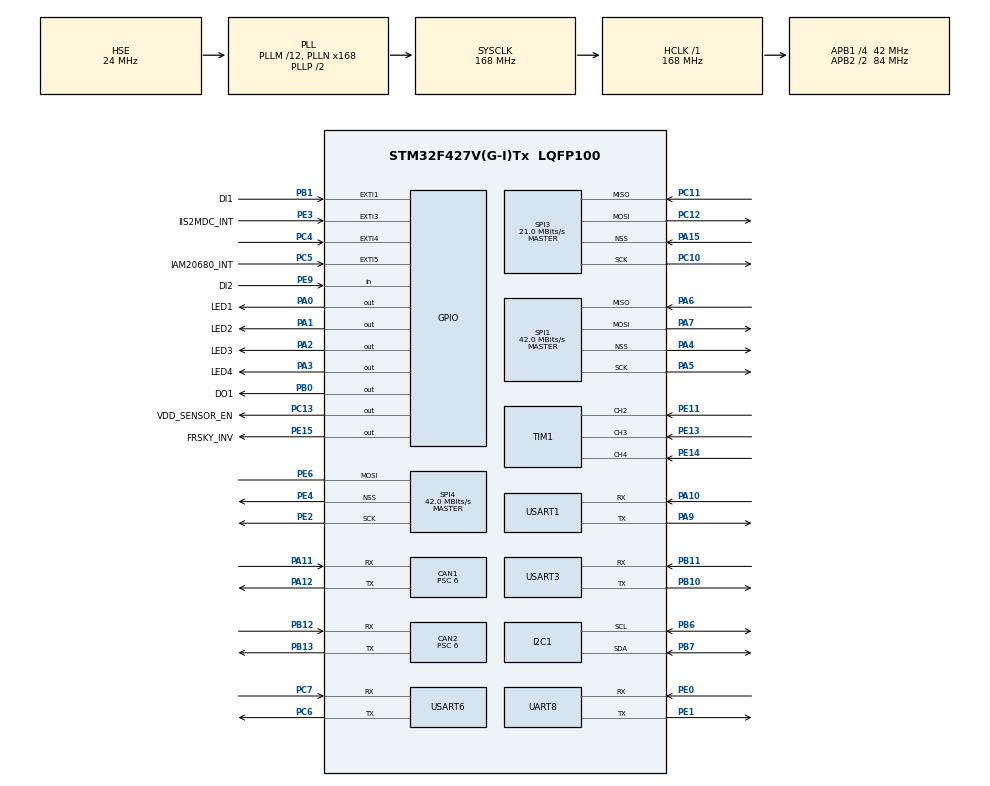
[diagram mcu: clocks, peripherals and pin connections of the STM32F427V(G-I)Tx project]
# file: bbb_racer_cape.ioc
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CAN1.BS1=CAN_BS1_11TQ
CAN1.BS2=CAN_BS2_2TQ
CAN1.CalculateBaudRate=500000
CAN1.CalculateTimeBit=1999.99
CAN1.CalculateTimeQuantum=142.85714285714286
CAN1.Prescaler=6
CAN2.BS1=CAN_BS1_11TQ
CAN2.BS2=CAN_BS2_2TQ
CAN2.CalculateBaudRate=500000
CAN2.CalculateTimeBit=1999.99
CAN2.CalculateTimeQuantum=142.85714285714286
CAN2.Prescaler=6
FREERTOS.Tasks01=defaultTask,24,128,StartDefaultTask,Default,NULL,Dynamic,NULL,NULL
FREERTOS.configENABLE_FPU=1
Mcu.Family=STM32F4
Mcu.Name=STM32F427V(G-I)Tx
Mcu.Package=LQFP100
NVIC.CAN1_RX0_IRQn=true\:5\:0\:false\:false\:true\:true\:true\:true
NVIC.CAN2_RX1_IRQn=true\:5\:0\:false\:false\:true\:true\:true\:true
NVIC.EXTI1_IRQn=true\:5\:0\:false\:false\:true\:true\:true\:true
NVIC.EXTI9_5_IRQn=true\:5\:0\:false\:false\:true\:true\:true\:true
NVIC.PriorityGroup=NVIC_PRIORITYGROUP_4
NVIC.TIM1_TRG_COM_TIM11_IRQn=true\:0\:0\:false\:false\:true\:false\:false\:true
NVIC.TimeBase=TIM1_TRG_COM_TIM11_IRQn
NVIC.TimeBaseIP=TIM11
NVIC.UART8_IRQn=true\:5\:0\:false\:false\:true\:true\:true\:true
NVIC.USART3_IRQn=true\:5\:0\:false\:false\:true\:true\:true\:true
NVIC.USART6_IRQn=true\:5\:0\:false\:false\:true\:true\:true\:true
PA0/WKUP.GPIO_Label=LED1
PA0/WKUP.Signal=GPIO_Output
PA1.GPIO_Label=LED2
PA1.Signal=GPIO_Output
PA10.Mode=Asynchronous
PA10.Signal=USART1_RX
PA11.Mode=CAN_Activate
PA11.Signal=CAN1_RX
PA12.Mode=CAN_Activate
PA12.Signal=CAN1_TX
PA13.Mode=Trace_Asynchronous_SW
PA13.Signal=SYS_JTMS-SWDIO
PA14.Mode=Trace_Asynchronous_SW
PA14.Signal=SYS_JTCK-SWCLK
PA15.Mode=NSS_Signal_Hard_Input
PA15.Signal=SPI3_NSS
PA2.GPIO_Label=LED3
PA2.Signal=GPIO_Output
PA3.GPIO_Label=LED4
PA3.Signal=GPIO_Output
PA4.Mode=NSS_Signal_Hard_Output
PA4.Signal=SPI1_NSS
PA5.Mode=Full_Duplex_Master
PA5.Signal=SPI1_SCK
PA6.Mode=Full_Duplex_Master
PA6.Signal=SPI1_MISO
PA7.Mode=Full_Duplex_Master
PA7.Signal=SPI1_MOSI
PA9.Mode=Asynchronous
PA9.Signal=USART1_TX
PB0.GPIO_Label=DO1
PB0.Signal=GPIO_Output
PB1.GPIO_Label=DI1
PB1.GPIO_PuPd=GPIO_PULLDOWN
PB1.Signal=GPXTI1
PB10.Mode=Asynchronous
PB10.Signal=USART3_TX
PB11.Mode=Asynchronous
PB11.Signal=USART3_RX
PB12.Mode=CAN_Activate
PB12.Signal=CAN2_RX
PB13.Mode=CAN_Activate
PB13.Signal=CAN2_TX
PB3.Mode=Trace_Asynchronous_SW
PB3.Signal=SYS_JTDO-SWO
PB6.Mode=I2C
PB6.Signal=I2C1_SCL
PB7.Mode=I2C
PB7.Signal=I2C1_SDA
PC10.Mode=Full_Duplex_Master
PC10.Signal=SPI3_SCK
PC11.Mode=Full_Duplex_Master
PC11.Signal=SPI3_MISO
PC12.Mode=Full_Duplex_Master
PC12.Signal=SPI3_MOSI
PC13.GPIO_Label=VDD_SENSOR_EN
PC13.Signal=GPIO_Output
PC4.Signal=GPXTI4
PC5.GPIO_Label=IAM20680_INT
PC5.Signal=GPXTI5
PC6.Mode=Asynchronous
PC6.Signal=USART6_TX
PC7.Mode=Asynchronous
PC7.Signal=USART6_RX
PE0.Mode=Asynchronous
PE0.Signal=UART8_RX
PE1.Mode=Asynchronous
PE1.Signal=UART8_TX
PE11.Signal=S_TIM1_CH2
PE13.Signal=S_TIM1_CH3
PE14.Signal=S_TIM1_CH4
PE15.GPIO_Label=FRSKY_INV
PE15.Signal=GPIO_Output
PE2.Mode=Simplex_Bidirectional_Master
PE2.Signal=SPI4_SCK
PE3.GPIO_Label=IIS2MDC_INT
PE3.Signal=GPXTI3
PE4.Mode=NSS_Signal_Hard_Output
PE4.Signal=SPI4_NSS
PE6.Mode=Simplex_Bidirectional_Master
PE6.Signal=SPI4_MOSI
PE9.GPIO_Label=DI2
PE9.Signal=GPIO_Input
PH0/OSC_IN.Mode=HSE-External-Oscillator
PH0/OSC_IN.Signal=RCC_OSC_IN
PH1/OSC_OUT.Mode=HSE-External-Oscillator
PH1/OSC_OUT.Signal=RCC_OSC_OUT
ProjectManager.HeapSize=0x200
ProjectManager.StackSize=0x400
ProjectManager.TargetToolchain=Makefile
RCC.48MHZClocksFreq_Value=84000000
RCC.AHBFreq_Value=168000000
RCC.APB1CLKDivider=RCC_HCLK_DIV4
RCC.APB1Freq_Value=42000000
RCC.APB1TimFreq_Value=84000000
RCC.APB2CLKDivider=RCC_HCLK_DIV2
RCC.APB2Freq_Value=84000000
RCC.APB2TimFreq_Value=168000000
RCC.CortexFreq_Value=168000000
RCC.HCLKFreq_Value=168000000
RCC.HSE_VALUE=24000000
RCC.HSI_VALUE=16000000
RCC.LSE_VALUE=32768
RCC.PLLM=12
RCC.PLLN=168
RCC.PLLSourceVirtual=RCC_PLLSOURCE_HSE
RCC.SYSCLKFreq_VALUE=168000000
RCC.SYSCLKSource=RCC_SYSCLKSOURCE_PLLCLK
RCC.VCOOutputFreq_Value=336000000
SH.S_TIM1_CH2.0=TIM1_CH2,Input_Capture2_from_TI2
SH.S_TIM1_CH3.0=TIM1_CH3,Input_Capture3_from_TI3
SH.S_TIM1_CH4.0=TIM1_CH4,Input_Capture4_from_TI4
SPI1.BaudRatePrescaler=SPI_BAUDRATEPRESCALER_2
SPI1.CalculateBaudRate=42.0 MBits/s
SPI1.Direction=SPI_DIRECTION_2LINES
SPI1.Mode=SPI_MODE_MASTER
SPI1.VirtualNSS=VM_NSSHARD
SPI1.VirtualType=VM_MASTER
SPI3.BaudRatePrescaler=SPI_BAUDRATEPRESCALER_2
SPI3.CalculateBaudRate=21.0 MBits/s
SPI3.Direction=SPI_DIRECTION_2LINES
SPI3.Mode=SPI_MODE_MASTER
SPI3.VirtualNSS=VM_NSSHARD
SPI3.VirtualType=VM_MASTER
SPI4.BaudRatePrescaler=SPI_BAUDRATEPRESCALER_2
SPI4.CalculateBaudRate=42.0 MBits/s
SPI4.Direction=SPI_DIRECTION_1LINE
SPI4.Mode=SPI_MODE_MASTER
SPI4.VirtualNSS=VM_NSSHARD
SPI4.VirtualType=VM_MASTER
TIM1.Channel-Input_Capture2_from_TI2=TIM_CHANNEL_2
TIM1.Channel-Input_Capture3_from_TI3=TIM_CHANNEL_3
TIM1.Channel-Input_Capture4_from_TI4=TIM_CHANNEL_4
UART8.VirtualMode=Asynchronous
USART1.VirtualMode=VM_ASYNC
USART3.VirtualMode=VM_ASYNC
USART6.VirtualMode=VM_ASYNC
VP_FREERTOS_VS_CMSIS_V2.Mode=CMSIS_V2
VP_SYS_VS_tim11.Mode=TIM11
board=custom

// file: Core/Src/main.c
/* USER CODE BEGIN Header */
/**
  ******************************************************************************
  * @file           : main.c
  * @brief          : Main program body
  ******************************************************************************
  * @attention
  *
  * <h2><center>&copy; Copyright (c) 2021 STMicroelectronics.
  * All rights reserved.</center></h2>
  *
  * This software component is licensed by ST under BSD 3-Clause license,
  * the "License"; You may not use this file except in compliance with the
  * License. You may obtain a copy of the License at:
  *                        opensource.org/licenses/BSD-3-Clause
  *
  ******************************************************************************
  */
/* USER CODE END Header */
#include "main.h"
#include "cmsis_os.h"
#include "can.h"
#include "i2c.h"
#include "spi.h"
#include "tim.h"
#include "usart.h"
#include "gpio.h"

/* USER CODE BEGIN Includes */
#include "testbed/testbed.h"
/* USER CODE END Includes */

void SystemClock_Config(void);
void MX_FREERTOS_Init(void);

int main(void)
{

  /* MCU Configuration--------------------------------------------------------*/

  /* Reset of all peripherals, Initializes the Flash interface and the Systick. */
  HAL_Init();

  /* Configure the system clock */
  SystemClock_Config();

  /* Initialize all configured peripherals */
  MX_GPIO_Init();
  MX_CAN1_Init();
  MX_CAN2_Init();
  MX_USART1_UART_Init();
  MX_USART3_UART_Init();
  MX_I2C1_Init();
  MX_SPI1_Init();
  MX_SPI3_Init();
  MX_SPI4_Init();
  MX_TIM1_Init();
  MX_USART6_UART_Init();
  MX_UART8_Init();
  /* USER CODE BEGIN 2 */
  StartTestbed();
  /* USER CODE END 2 */

  /* Init scheduler */
  osKernelInitialize();  /* Call init function for freertos objects (in freertos.c) */
  MX_FREERTOS_Init();
  /* Start scheduler */
  osKernelStart();

  /* We should never get here as control is now taken by the scheduler */
  /* Infinite loop */
  while (1)
  {

  }
}

void SystemClock_Config(void)
{
  RCC_OscInitTypeDef RCC_OscInitStruct = {0};
  RCC_ClkInitTypeDef RCC_ClkInitStruct = {0};

  /** Configure the main internal regulator output voltage
  */
  __HAL_RCC_PWR_CLK_ENABLE();
  __HAL_PWR_VOLTAGESCALING_CONFIG(PWR_REGULATOR_VOLTAGE_SCALE1);
  /** Initializes the RCC Oscillators according to the specified parameters
  * in the RCC_OscInitTypeDef structure.
  */
  RCC_OscInitStruct.OscillatorType = RCC_OSCILLATORTYPE_HSE;
  RCC_OscInitStruct.HSEState = RCC_HSE_ON;
  RCC_OscInitStruct.PLL.PLLState = RCC_PLL_ON;
  RCC_OscInitStruct.PLL.PLLSource = RCC_PLLSOURCE_HSE;
  RCC_OscInitStruct.PLL.PLLM = 12;
  RCC_OscInitStruct.PLL.PLLN = 168;
  RCC_OscInitStruct.PLL.PLLP = RCC_PLLP_DIV2;
  RCC_OscInitStruct.PLL.PLLQ = 4;
  if (HAL_RCC_OscConfig(&RCC_OscInitStruct) != HAL_OK)
  {
    Error_Handler();
  }
  /** Initializes the CPU, AHB and APB buses clocks
  */
  RCC_ClkInitStruct.ClockType = RCC_CLOCKTYPE_HCLK|RCC_CLOCKTYPE_SYSCLK
                              |RCC_CLOCKTYPE_PCLK1|RCC_CLOCKTYPE_PCLK2;
  RCC_ClkInitStruct.SYSCLKSource = RCC_SYSCLKSOURCE_PLLCLK;
  RCC_ClkInitStruct.AHBCLKDivider = RCC_SYSCLK_DIV1;
  RCC_ClkInitStruct.APB1CLKDivider = RCC_HCLK_DIV4;
  RCC_ClkInitStruct.APB2CLKDivider = RCC_HCLK_DIV2;

  if (HAL_RCC_ClockConfig(&RCC_ClkInitStruct, FLASH_LATENCY_5) != HAL_OK)
  {
    Error_Handler();
  }
}

 /**
  * @brief  Period elapsed callback in non blocking mode
  * @note   This function is called  when TIM11 interrupt took place, inside
  * HAL_TIM_IRQHandler(). It makes a direct call to HAL_IncTick() to increment
  * a global variable "uwTick" used as application time base.
  * @param  htim : TIM handle
  * @retval None
  */
void HAL_TIM_PeriodElapsedCallback(TIM_HandleTypeDef *htim)
{
  if (htim->Instance == TIM11) {
    HAL_IncTick();
  }
}

void Error_Handler(void)
{
  __disable_irq();
  while (1)
  {
  }
}

/************************ (C) COPYRIGHT STMicroelectronics *****END OF FILE****/
